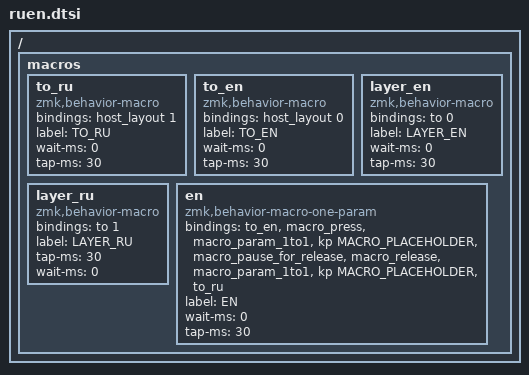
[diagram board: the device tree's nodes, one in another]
#include <behaviors.dtsi>
#include <dt-bindings/zmk/keys.h>
#include "host_layout.dtsi"

/*
 * Shared RuEn macros.
 * layer_en/layer_ru: firmware layer only — Mac layout via HID 0xAD.
 * to_en/to_ru: HID 0xAE host layout, wait for ACK 0xAF, then continue.
 *   `en` holds the ABC scancode until release, then `&to_ru`.
 *   No extra tap after release (that raced TIS back to Russian → Ё on S-\\).
 *   No Ctrl+Shift+1/2 (Russian Shift+2 leaks ").
 */

/ {
    macros {
        to_ru: to_ru {
            compatible = "zmk,behavior-macro";
            #binding-cells = <0>;
            bindings = <&host_layout 1>;
            label = "TO_RU";
            wait-ms = <0>;
            tap-ms = <30>;
        };

        to_en: to_en {
            compatible = "zmk,behavior-macro";
            #binding-cells = <0>;
            bindings = <&host_layout 0>;
            label = "TO_EN";
            wait-ms = <0>;
            tap-ms = <30>;
        };

        layer_en: layer_en {
            compatible = "zmk,behavior-macro";
            #binding-cells = <0>;
            bindings = <&to 0>;
            label = "LAYER_EN";
            wait-ms = <0>;
            tap-ms = <30>;
        };

        layer_ru: layer_ru {
            compatible = "zmk,behavior-macro";
            #binding-cells = <0>;
            bindings = <&to 1>;
            label = "LAYER_RU";
            tap-ms = <30>;
            wait-ms = <0>;
        };

        en: en {
            compatible = "zmk,behavior-macro-one-param";
            #binding-cells = <1>;
            bindings =
                <&to_en>,
                <&macro_press>,
                <&macro_param_1to1 &kp MACRO_PLACEHOLDER>,
                <&macro_pause_for_release>,
                <&macro_release>,
                <&macro_param_1to1 &kp MACRO_PLACEHOLDER>,
                <&to_ru>;

            label = "EN";
            wait-ms = <0>;
            tap-ms = <30>;
        };
    };
};
